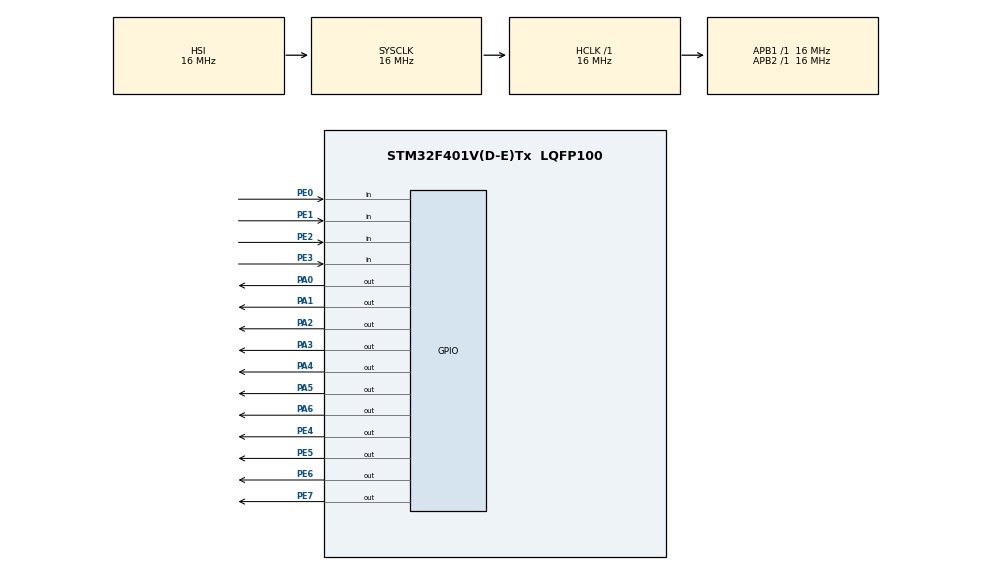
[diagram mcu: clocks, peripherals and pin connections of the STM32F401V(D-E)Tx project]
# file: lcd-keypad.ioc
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Mcu.Family=STM32F4
Mcu.Name=STM32F401V(D-E)Tx
Mcu.Package=LQFP100
NVIC.PriorityGroup=NVIC_PRIORITYGROUP_4
PA0-WKUP.Signal=GPIO_Output
PA1.Signal=GPIO_Output
PA2.Signal=GPIO_Output
PA3.Signal=GPIO_Output
PA4.Signal=GPIO_Output
PA5.Signal=GPIO_Output
PA6.Signal=GPIO_Output
PE0.Signal=GPIO_Input
PE1.Signal=GPIO_Input
PE2.Signal=GPIO_Input
PE3.Signal=GPIO_Input
PE4.Signal=GPIO_Output
PE5.Signal=GPIO_Output
PE6.Signal=GPIO_Output
PE7.Signal=GPIO_Output
PH0\ -\ OSC_IN.Mode=HSE-External-Oscillator
PH0\ -\ OSC_IN.Signal=RCC_OSC_IN
PH1\ -\ OSC_OUT.Mode=HSE-External-Oscillator
PH1\ -\ OSC_OUT.Signal=RCC_OSC_OUT
ProjectManager.HeapSize=0x200
ProjectManager.StackSize=0x400
ProjectManager.TargetToolchain=MDK-ARM V5.32
RCC.48MHZClocksFreq_Value=75000000
RCC.AHBFreq_Value=16000000
RCC.APB1Freq_Value=16000000
RCC.APB2Freq_Value=16000000
RCC.CortexFreq_Value=16000000
RCC.HSE_VALUE=25000000
RCC.HSI_VALUE=16000000
RCC.LSE_VALUE=32768
RCC.PLLSourceVirtual=RCC_PLLSOURCE_HSE
RCC.SYSCLKFreq_VALUE=16000000
RCC.VCOOutputFreq_Value=300000000
board=custom

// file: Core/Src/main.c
/* USER CODE BEGIN Header */
/**
 ******************************************************************************
 * @file           : main.c
 * @brief          : Main program body
 ******************************************************************************
 * @attention
 *
 * Copyright (c) 2025 STMicroelectronics.
 * All rights reserved.
 *
 * This software is licensed under terms that can be found in the LICENSE file
 * in the root directory of this software component.
 * If no LICENSE file comes with this software, it is provided AS-IS.
 *
 ******************************************************************************
 */
/* USER CODE END Header */
#include "main.h"

/* USER CODE BEGIN Includes */
#include "STM_MY_LCD16X2.h"
#include "keypad.h"
#include <stdio.h>
/* USER CODE END Includes */

void SystemClock_Config(void);
static void MX_GPIO_Init(void);

int main(void)
{
	/* USER CODE BEGIN 1 */
	char str[16];
	char data_key[16] = {
		'7', '8', '9', '/',
		'4', '5', '6', '*',
		'1', '2', '3', '+',
		'C', '0', '=', '-'
	};

	/* USER CODE END 1 */

	/* MCU Configuration--------------------------------------------------------*/

	/* Reset of all peripherals, Initializes the Flash interface and the Systick. */
	HAL_Init();

	/* Configure the system clock */
	SystemClock_Config();

	/* Initialize all configured peripherals */
	MX_GPIO_Init();
	/* USER CODE BEGIN 2 */
	LCD1602_Begin4BIT(GPIOA, GPIO_PIN_0, GPIO_PIN_1, GPIOA, GPIO_PIN_3, GPIO_PIN_4, GPIO_PIN_5, GPIO_PIN_6);
	/* USER CODE END 2 */

	/* Infinite loop */
	while (1)
	{

		int num1 = 0, num2 = 0, result = 0;
		char oper;

		keypad_write(0xf0);
		while (keypad_read() == 0xf0)
			;
		int keypress = keypad();
		if (keypress != 100)
		{
			num1 = data_key[keypress] - '0';
			sprintf(str, "%c", data_key[keypress]);
			LCD1602_print(str);
			HAL_Delay(500);
		}

		keypad_write(0xf0);
		while (keypad_read() == 0xf0)
			;
		keypress = keypad();
		if (keypress != 100)
		{
			oper = data_key[keypress];
			sprintf(str, "%c", data_key[keypress]);
			LCD1602_print(str);
			HAL_Delay(500);
		}

		keypad_write(0xf0);
		while (keypad_read() == 0xf0)
			;
		keypress = keypad();
		if (keypress != 100)
		{
			num2 = data_key[keypress] - '0';
			sprintf(str, "%c", data_key[keypress]);
			LCD1602_print(str);
			HAL_Delay(500);
		}

		keypad_write(0xf0);
		while (keypad_read() == 0xf0)
			;
		keypress = keypad();
		if (keypress != 100)
		{
			sprintf(str, "%c", data_key[keypress]);
			LCD1602_print(str);
			if (data_key[keypress] != '=')
			{
				LCD1602_2ndLine();
				LCD1602_print("ERROR");
				HAL_Delay(500);
				LCD1602_clear();
			}
			else
			{
				if (oper == '-')
				{
					result = num1 - num2;
					LCD1602_PrintInt(result);
					HAL_Delay(500);
				}
				else if (oper == '+')
				{
					result = num1 + num2;
					LCD1602_PrintInt(result);
					HAL_Delay(500);
				}
				else if (oper == '*')
				{
					result = num1 * num2;
					LCD1602_PrintInt(result);
					HAL_Delay(500);
				}
				else if (oper == '/')
				{
					result = num1 / num2;
					LCD1602_PrintInt(result);
					HAL_Delay(500);
				}
				else
				{
					LCD1602_2ndLine();
					LCD1602_print("ERROR");
					HAL_Delay(500);
					LCD1602_clear();
				}
				HAL_Delay(500);
				LCD1602_clear();
			}
		}
	}
	/* USER CODE END 3 */
}

void SystemClock_Config(void)
{
	RCC_OscInitTypeDef RCC_OscInitStruct = { 0 };
	RCC_ClkInitTypeDef RCC_ClkInitStruct = { 0 };

	/** Configure the main internal regulator output voltage
	 */
	__HAL_RCC_PWR_CLK_ENABLE();
	__HAL_PWR_VOLTAGESCALING_CONFIG(PWR_REGULATOR_VOLTAGE_SCALE2);

	/** Initializes the RCC Oscillators according to the specified parameters
	 * in the RCC_OscInitTypeDef structure.
	 */
	RCC_OscInitStruct.OscillatorType = RCC_OSCILLATORTYPE_HSI;
	RCC_OscInitStruct.HSIState = RCC_HSI_ON;
	RCC_OscInitStruct.HSICalibrationValue = RCC_HSICALIBRATION_DEFAULT;
	RCC_OscInitStruct.PLL.PLLState = RCC_PLL_NONE;
	if (HAL_RCC_OscConfig(&RCC_OscInitStruct) != HAL_OK)
	{
		Error_Handler();
	}

	/** Initializes the CPU, AHB and APB buses clocks
	 */
	RCC_ClkInitStruct.ClockType = RCC_CLOCKTYPE_HCLK | RCC_CLOCKTYPE_SYSCLK
		| RCC_CLOCKTYPE_PCLK1 | RCC_CLOCKTYPE_PCLK2;
	RCC_ClkInitStruct.SYSCLKSource = RCC_SYSCLKSOURCE_HSI;
	RCC_ClkInitStruct.AHBCLKDivider = RCC_SYSCLK_DIV1;
	RCC_ClkInitStruct.APB1CLKDivider = RCC_HCLK_DIV1;
	RCC_ClkInitStruct.APB2CLKDivider = RCC_HCLK_DIV1;

	if (HAL_RCC_ClockConfig(&RCC_ClkInitStruct, FLASH_LATENCY_0) != HAL_OK)
	{
		Error_Handler();
	}
}

static void MX_GPIO_Init(void)
{
	GPIO_InitTypeDef GPIO_InitStruct = { 0 };

	/* GPIO Ports Clock Enable */
	__HAL_RCC_GPIOE_CLK_ENABLE();
	__HAL_RCC_GPIOH_CLK_ENABLE();
	__HAL_RCC_GPIOA_CLK_ENABLE();

	/*Configure GPIO pin Output Level */
	HAL_GPIO_WritePin(GPIOE, GPIO_PIN_4 | GPIO_PIN_5 | GPIO_PIN_6 | GPIO_PIN_7, GPIO_PIN_RESET);

	/*Configure GPIO pin Output Level */
	HAL_GPIO_WritePin(GPIOA, GPIO_PIN_0 | GPIO_PIN_1 | GPIO_PIN_2 | GPIO_PIN_3 | GPIO_PIN_4 | GPIO_PIN_5 | GPIO_PIN_6, GPIO_PIN_RESET);

	/*Configure GPIO pins : PE2 PE3 PE0 PE1 */
	GPIO_InitStruct.Pin = GPIO_PIN_2 | GPIO_PIN_3 | GPIO_PIN_0 | GPIO_PIN_1;
	GPIO_InitStruct.Mode = GPIO_MODE_INPUT;
	GPIO_InitStruct.Pull = GPIO_NOPULL;
	HAL_GPIO_Init(GPIOE, &GPIO_InitStruct);

	/*Configure GPIO pins : PE4 PE5 PE6 PE7 */
	GPIO_InitStruct.Pin = GPIO_PIN_4 | GPIO_PIN_5 | GPIO_PIN_6 | GPIO_PIN_7;
	GPIO_InitStruct.Mode = GPIO_MODE_OUTPUT_PP;
	GPIO_InitStruct.Pull = GPIO_NOPULL;
	GPIO_InitStruct.Speed = GPIO_SPEED_FREQ_LOW;
	HAL_GPIO_Init(GPIOE, &GPIO_InitStruct);

	/*Configure GPIO pins : PA0 PA1 PA2 PA3
							 PA4 PA5 PA6 */
	GPIO_InitStruct.Pin = GPIO_PIN_0 | GPIO_PIN_1 | GPIO_PIN_2 | GPIO_PIN_3
		| GPIO_PIN_4 | GPIO_PIN_5 | GPIO_PIN_6;
	GPIO_InitStruct.Mode = GPIO_MODE_OUTPUT_PP;
	GPIO_InitStruct.Pull = GPIO_NOPULL;
	GPIO_InitStruct.Speed = GPIO_SPEED_FREQ_LOW;
	HAL_GPIO_Init(GPIOA, &GPIO_InitStruct);
}

void Error_Handler(void)
{
	__disable_irq();
	while (1)
	{
	}
}
